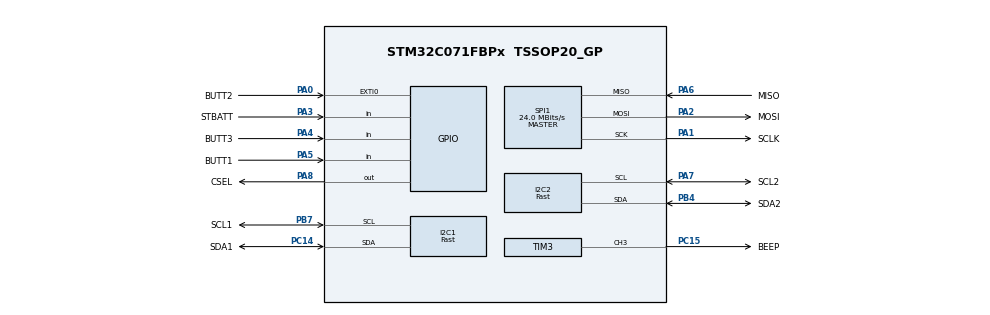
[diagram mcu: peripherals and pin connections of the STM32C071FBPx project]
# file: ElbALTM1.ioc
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I2C1.I2C_Speed_Mode=I2C_Fast
I2C1.Timing=0x0090194B
I2C2.I2C_Speed_Mode=I2C_Fast
I2C2.Timing=0x0090194B
Mcu.Family=STM32C0
Mcu.Name=STM32C071FBPx
Mcu.Package=TSSOP20_GP
PA0.GPIO_Label=BUTT2
PA0.GPIO_ModeDefaultEXTI=GPIO_MODE_IT_FALLING
PA0.GPIO_PuPd=GPIO_PULLUP
PA0.Signal=GPXTI0
PA1.GPIO_Label=SCLK
PA1.GPIO_Speed=GPIO_SPEED_FREQ_VERY_HIGH
PA1.Mode=Full_Duplex_Master
PA1.Signal=SPI1_SCK
PA11\ [PA9].Signal=USB_DM
PA12\ [PA10].Signal=USB_DP
PA13.GPIO_Label=SWDIO
PA13.Mode=Serial_Wire
PA13.Signal=DEBUG_SWDIO
PA14-BOOT0.GPIO_Label=SWCLK
PA14-BOOT0.Mode=Serial_Wire
PA14-BOOT0.Signal=DEBUG_SWCLK
PA14-BOOT0__PA15.StandardMode=true
PA2.GPIO_Label=MOSI
PA2.GPIO_Speed=GPIO_SPEED_FREQ_VERY_HIGH
PA2.Mode=Full_Duplex_Master
PA2.Signal=SPI1_MOSI
PA3.GPIO_Label=STBATT
PA3.GPIO_PuPd=GPIO_PULLUP
PA3.Signal=GPIO_Input
PA4.GPIO_Label=BUTT3
PA4.GPIO_Mode=GPIO_MODE_INPUT
PA4.GPIO_PuPd=GPIO_PULLUP
PA4.Signal=GPIO_Input
PA5.GPIO_Label=BUTT1
PA5.GPIO_Mode=GPIO_MODE_INPUT
PA5.GPIO_PuPd=GPIO_PULLUP
PA5.Signal=GPIO_Input
PA6.GPIO_Label=MISO
PA6.GPIO_Speed=GPIO_SPEED_FREQ_VERY_HIGH
PA6.Mode=Full_Duplex_Master
PA6.Signal=SPI1_MISO
PA7.GPIO_Label=SCL2
PA7.GPIO_Pu=GPIO_PULLUP
PA7.GPIO_Speed=GPIO_SPEED_FREQ_VERY_HIGH
PA7.Mode=I2C
PA7.Signal=I2C2_SCL
PA8.GPIO_Label=CSEL
PA8.GPIO_Speed=GPIO_SPEED_FREQ_VERY_HIGH
PA8.PinState=GPIO_PIN_SET
PA8.Signal=GPIO_Output
PB3__PB4__PB5__PB6.StandardMode=true
PB4.GPIO_Label=SDA2
PB4.GPIO_Pu=GPIO_PULLUP
PB4.GPIO_Speed=GPIO_SPEED_FREQ_VERY_HIGH
PB4.Mode=I2C
PB4.Signal=I2C2_SDA
PB7.GPIO_FM7=SYSCFG_FASTMODEPLUS_PB7
PB7.GPIO_Label=SCL1
PB7.GPIO_Pu=GPIO_PULLUP
PB7.GPIO_Speed=GPIO_SPEED_FREQ_VERY_HIGH
PB7.Mode=I2C
PB7.Signal=I2C1_SCL
PB7__PB8.StandardMode=true
PC14-OSCX_IN(PC14).GPIO_FMPC14=SYSCFG_FASTMODEPLUS_PC14
PC14-OSCX_IN(PC14).GPIO_Label=SDA1
PC14-OSCX_IN(PC14).GPIO_Pu=GPIO_PULLUP
PC14-OSCX_IN(PC14).GPIO_Speed=GPIO_SPEED_FREQ_VERY_HIGH
PC14-OSCX_IN(PC14).Mode=I2C
PC14-OSCX_IN(PC14).Signal=I2C1_SDA
PC15-OSCX_OUT(PC15).GPIO_Label=BEEP
PC15-OSCX_OUT(PC15).GPIO_PuPd=GPIO_PULLDOWN
PC15-OSCX_OUT(PC15).GPIO_Speed=GPIO_SPEED_FREQ_VERY_HIGH
PC15-OSCX_OUT(PC15).Signal=S_TIM3_CH3
ProjectManager.HeapSize=0x200
ProjectManager.StackSize=0x400
ProjectManager.TargetToolchain=CMake
RCC.ADCFreq_Value=48000000
RCC.AHBFreq_Value=48000000
RCC.CortexFreq_Value=48000000
RCC.EXTERNAL_CLOCK_VALUE=12288000
RCC.HCLKFreq_Value=48000000
RCC.HSE_VALUE=8000000
RCC.HSI48_VALUE=48000000
RCC.HSI_VALUE=48000000
RCC.LSE_VALUE=32768
RCC.SYSCLKFreq_VALUE=48000000
RCC.SYSCLKSource=RCC_SYSCLKSOURCE_HSIUSB48
SH.S_TIM3_CH3.0=TIM3_CH3,PWM Generation3 CH3
SPI1.CalculateBaudRate=24.0 MBits/s
SPI1.Direction=SPI_DIRECTION_2LINES
SPI1.Mode=SPI_MODE_MASTER
SPI1.VirtualType=VM_MASTER
TIM3.AutoReloadPreload=TIM_AUTORELOAD_PRELOAD_ENABLE
TIM3.Channel-PWM\ Generation3\ CH3=TIM_CHANNEL_3
TIM3.Period=4000
TIM3.Prescaler=48-1
TIM3.Pulse-PWM\ Generation3\ CH3=2000
VP_TIM3_VS_ClockSourceINT.Mode=Internal
board=custom

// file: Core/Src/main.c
/* USER CODE BEGIN Header */
/**
  ******************************************************************************
  * @file           : main.c
  * @brief          : Main program body
  ******************************************************************************
  * @attention
  *
  * Copyright (c) 2025 STMicroelectronics.
  * All rights reserved.
  *
  * This software is licensed under terms that can be found in the LICENSE file
  * in the root directory of this software component.
  * If no LICENSE file comes with this software, it is provided AS-IS.
  *
  ******************************************************************************
  */
/* USER CODE END Header */
#include "main.h"
#include "i2c.h"
#include "spi.h"
#include "tim.h"
#include "gpio.h"

/* USER CODE BEGIN Includes */
#include "usr.h"
/* USER CODE END Includes */

void SystemClock_Config(void);

int main(void)
{

  /* MCU Configuration--------------------------------------------------------*/

  /* Reset of all peripherals, Initializes the Flash interface and the Systick. */
  HAL_Init();

  /* Configure the system clock */
  SystemClock_Config();

  /* Initialize all configured peripherals */
  MX_GPIO_Init();
  MX_I2C1_Init();
  MX_TIM3_Init();
  MX_I2C2_Init();
  MX_SPI1_Init();
  /* USER CODE BEGIN 2 */
  usr_setup();
  /* USER CODE END 2 */

  /* Infinite loop */
  /* USER CODE BEGIN WHILE */
  while (1)
  {
    usr_main();
    /* USER CODE END WHILE */

  }
}

void SystemClock_Config(void)
{
  RCC_OscInitTypeDef RCC_OscInitStruct = {0};
  RCC_ClkInitTypeDef RCC_ClkInitStruct = {0};

  __HAL_FLASH_SET_LATENCY(FLASH_LATENCY_1);

  /** Initializes the RCC Oscillators according to the specified parameters
  * in the RCC_OscInitTypeDef structure.
  */
  RCC_OscInitStruct.OscillatorType = RCC_OSCILLATORTYPE_HSI48;
  RCC_OscInitStruct.HSI48State = RCC_HSI48_ON;

  if (HAL_RCC_OscConfig(&RCC_OscInitStruct) != HAL_OK)
  {
    Error_Handler();
  }

  /** Initializes the CPU, AHB and APB buses clocks
  */
  RCC_ClkInitStruct.ClockType = RCC_CLOCKTYPE_HCLK|RCC_CLOCKTYPE_SYSCLK
                              |RCC_CLOCKTYPE_PCLK1;
  RCC_ClkInitStruct.SYSCLKSource = RCC_SYSCLKSOURCE_HSIUSB48;
  RCC_ClkInitStruct.SYSCLKDivider = RCC_SYSCLK_DIV1;
  RCC_ClkInitStruct.AHBCLKDivider = RCC_HCLK_DIV1;
  RCC_ClkInitStruct.APB1CLKDivider = RCC_APB1_DIV1;

  if (HAL_RCC_ClockConfig(&RCC_ClkInitStruct, FLASH_LATENCY_1) != HAL_OK)
  {
    Error_Handler();
  }
}

void Error_Handler(void)
{
  __disable_irq();
  while (1)
  {
  }
}
#ifdef USE_FULL_ASSERT
/**
  * @brief  Reports the name of the source file and the source line number
  *         where the assert_param error has occurred.
  * @param  file: pointer to the source file name
  * @param  line: assert_param error line source number
  * @retval None
  */
void assert_failed(uint8_t *file, uint32_t line)
{
  /* USER CODE BEGIN 6 */
  UNUSED(file);
  UNUSED(line);
  /* User can add his own implementation to report the file name and line number,
     ex: printf("Wrong parameters value: file %s on line %d\r\n", file, line) */
  /* USER CODE END 6 */
}
#endif /* USE_FULL_ASSERT */
